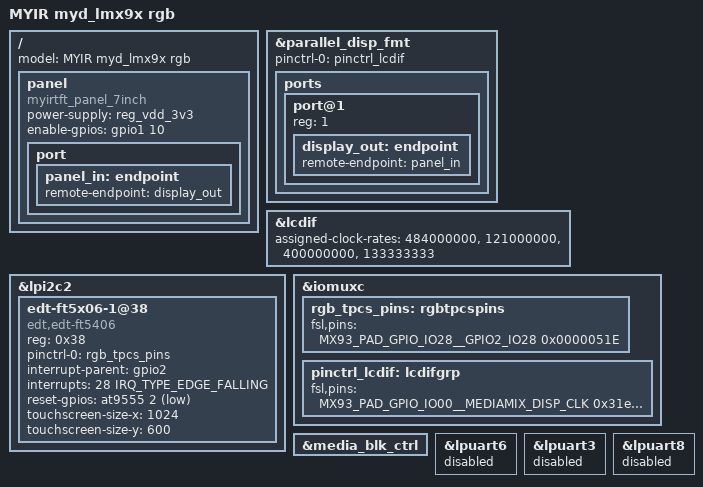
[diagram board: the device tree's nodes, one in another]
// SPDX-License-Identifier: (GPL-2.0+ OR MIT)
/*
 * Copyright 2026 MYIR
 */

#include "myd-lmx9x-11x11.dts"
/ {
	model = "MYIR myd_lmx9x rgb ";
	panel {
		compatible = "myirtft_panel_7inch";
		power-supply = <&reg_vdd_3v3>;
		enable-gpios = <&gpio1 10 GPIO_ACTIVE_HIGH>;
	
		port {
			panel_in: endpoint {
				remote-endpoint = <&display_out>;
			};
		};
	};
};

&parallel_disp_fmt {
	pinctrl-names = "default";
	pinctrl-0 = <&pinctrl_lcdif>;
	// fsl,interface-pix-fmt = "rgb888";
	status = "okay";

	ports {
		port@1 {
			reg = <1>;

			display_out: endpoint {
				remote-endpoint = <&panel_in>;
			};
		};
	};
};



&lcdif {
	assigned-clock-rates = <484000000>, <121000000>, <400000000>, <133333333>;
	status = "okay";
};


&lpi2c2 {
	edt-ft5x06-1@38 {
		compatible = "edt,edt-ft5406";
		reg = <0x38>;
		pinctrl-names = "default";
		pinctrl-0 = <&rgb_tpcs_pins>;
		interrupt-parent = <&gpio2>;
		interrupts = <28 IRQ_TYPE_EDGE_FALLING>;
		reset-gpios = <&at9555 2 GPIO_ACTIVE_LOW>;
		touchscreen-size-x=<1024>;
		touchscreen-size-y=<600>;
		status = "okay";
	};
};


&iomuxc {
	rgb_tpcs_pins: rgbtpcspins {
		fsl,pins = <
			MX93_PAD_GPIO_IO28__GPIO2_IO28             0x0000051E
		>;
	};

	pinctrl_lcdif: lcdifgrp {
		fsl,pins = <
			MX93_PAD_GPIO_IO00__MEDIAMIX_DISP_CLK		0x31e
			MX93_PAD_GPIO_IO01__MEDIAMIX_DISP_DE		0x31e
			MX93_PAD_GPIO_IO02__MEDIAMIX_DISP_VSYNC		0x31e
			MX93_PAD_GPIO_IO03__MEDIAMIX_DISP_HSYNC		0x31e
			MX93_PAD_GPIO_IO04__MEDIAMIX_DISP_DATA00	0x31e
			MX93_PAD_GPIO_IO05__MEDIAMIX_DISP_DATA01	0x31e
			MX93_PAD_GPIO_IO06__MEDIAMIX_DISP_DATA02	0x31e
			MX93_PAD_GPIO_IO07__MEDIAMIX_DISP_DATA03	0x31e
			MX93_PAD_GPIO_IO08__MEDIAMIX_DISP_DATA04	0x31e
			MX93_PAD_GPIO_IO09__MEDIAMIX_DISP_DATA05	0x31e
			MX93_PAD_GPIO_IO10__MEDIAMIX_DISP_DATA06	0x31e
			MX93_PAD_GPIO_IO11__MEDIAMIX_DISP_DATA07	0x31e
			MX93_PAD_GPIO_IO12__MEDIAMIX_DISP_DATA08	0x31e
			MX93_PAD_GPIO_IO13__MEDIAMIX_DISP_DATA09	0x31e
			MX93_PAD_GPIO_IO14__MEDIAMIX_DISP_DATA10	0x31e
			MX93_PAD_GPIO_IO15__MEDIAMIX_DISP_DATA11	0x31e
			MX93_PAD_GPIO_IO16__MEDIAMIX_DISP_DATA12	0x31e
			MX93_PAD_GPIO_IO17__MEDIAMIX_DISP_DATA13	0x31e
			MX93_PAD_GPIO_IO18__MEDIAMIX_DISP_DATA14	0x31e
			MX93_PAD_GPIO_IO19__MEDIAMIX_DISP_DATA15	0x31e
			MX93_PAD_GPIO_IO20__MEDIAMIX_DISP_DATA16	0x31e
			MX93_PAD_GPIO_IO21__MEDIAMIX_DISP_DATA17	0x31e
			MX93_PAD_GPIO_IO22__MEDIAMIX_DISP_DATA18   0x0000051E
            MX93_PAD_GPIO_IO23__MEDIAMIX_DISP_DATA19   0x0000051E
            MX93_PAD_GPIO_IO24__MEDIAMIX_DISP_DATA20   0x0000051E
            MX93_PAD_GPIO_IO25__MEDIAMIX_DISP_DATA21   0x0000051E
            MX93_PAD_GPIO_IO26__MEDIAMIX_DISP_DATA22   0x0000051E
            MX93_PAD_GPIO_IO27__MEDIAMIX_DISP_DATA23   0x0000051E
		>;
	};
};

&media_blk_ctrl {
	status = "okay";
};

// &lt9611_hdmi {
// 	status = "disabled";
// };

/* pin conflicts */
&lpuart6{
	status = "disabled";
};

&lpuart3{
	status = "disabled";
};
&lpuart8{
	status = "disabled";
};
